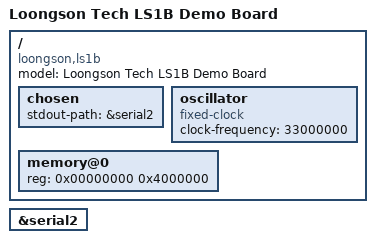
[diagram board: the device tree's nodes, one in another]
/dts-v1/;

#include "ls1b.dtsi"

/ {
	model = "Loongson Tech LS1B Demo Board";
	compatible = "loongson,ls1b";

	chosen {
		stdout-path = &serial2;
	};

	oscillator: oscillator {
			#clock-cells = <0>;
			compatible = "fixed-clock";
			clock-frequency = <33000000>;
	};

	memory@0 {
		device_type = "memory";
		reg = <0x00000000 0x4000000>;
	};
};

&serial2 {
	status = "okay";
};
